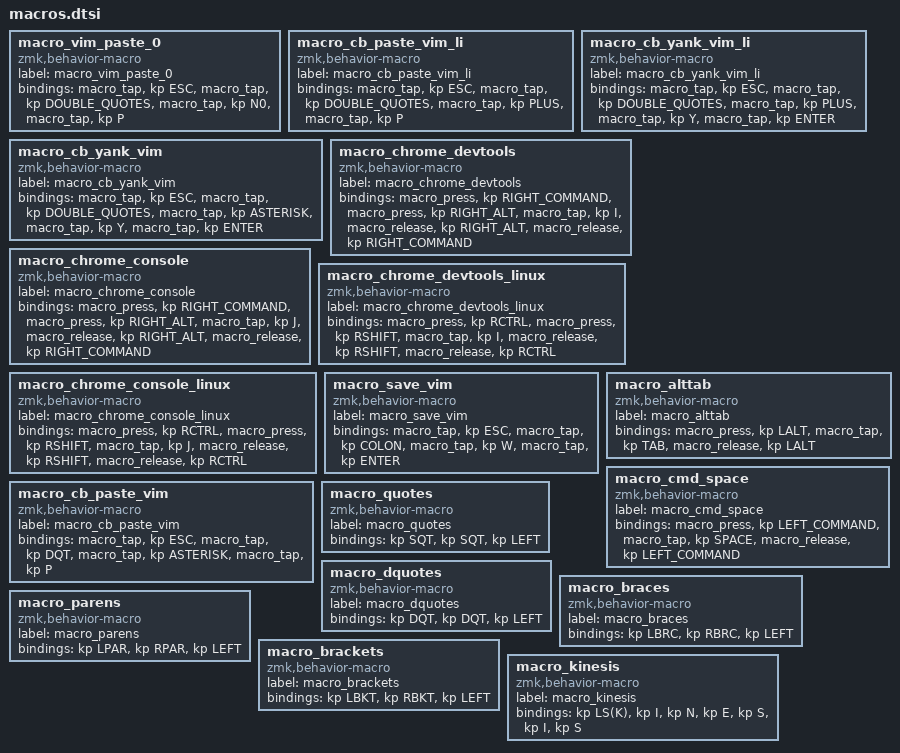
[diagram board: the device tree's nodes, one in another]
macro_vim_paste_0: macro_vim_paste_0{
compatible = "zmk,behavior-macro";
label = "macro_vim_paste_0";
#binding-cells = <0>;
bindings = <&macro_tap &kp ESC>, <&macro_tap &kp DOUBLE_QUOTES>, <&macro_tap &kp N0>, <&macro_tap &kp P>;
};
macro_cb_paste_vim_li: macro_cb_paste_vim_li{
compatible = "zmk,behavior-macro";
label = "macro_cb_paste_vim_li";
#binding-cells = <0>;
bindings = <&macro_tap &kp ESC>, <&macro_tap &kp DOUBLE_QUOTES>, <&macro_tap &kp PLUS>, <&macro_tap &kp P>;
};
macro_cb_yank_vim_li: macro_cb_yank_vim_li{
compatible = "zmk,behavior-macro";
label = "macro_cb_yank_vim_li";
#binding-cells = <0>;
bindings = <&macro_tap &kp ESC>, <&macro_tap &kp DOUBLE_QUOTES>, <&macro_tap &kp PLUS>, <&macro_tap &kp Y>, <&macro_tap &kp ENTER>;
};
macro_cb_yank_vim: macro_cb_yank_vim{
compatible = "zmk,behavior-macro";
label = "macro_cb_yank_vim";
#binding-cells = <0>;
bindings = <&macro_tap &kp ESC>, <&macro_tap &kp DOUBLE_QUOTES>, <&macro_tap &kp ASTERISK>, <&macro_tap &kp Y>, <&macro_tap &kp ENTER>;
};
macro_chrome_devtools: macro_chrome_devtools{
compatible = "zmk,behavior-macro";
label = "macro_chrome_devtools";
#binding-cells = <0>;
bindings = <&macro_press &kp RIGHT_COMMAND>, <&macro_press &kp RIGHT_ALT>, <&macro_tap &kp I>, <&macro_release &kp RIGHT_ALT>, <&macro_release &kp RIGHT_COMMAND>;
};
macro_chrome_console: macro_chrome_console{
compatible = "zmk,behavior-macro";
label = "macro_chrome_console";
#binding-cells = <0>;
bindings = <&macro_press &kp RIGHT_COMMAND>, <&macro_press &kp RIGHT_ALT>, <&macro_tap &kp J>, <&macro_release &kp RIGHT_ALT>, <&macro_release &kp RIGHT_COMMAND>;
};
macro_chrome_devtools_linux: macro_chrome_devtools_linux{
compatible = "zmk,behavior-macro";
label = "macro_chrome_devtools_linux";
#binding-cells = <0>;
bindings = <&macro_press &kp RCTRL>, <&macro_press &kp RSHIFT>, <&macro_tap &kp I>, <&macro_release &kp RSHIFT>, <&macro_release &kp RCTRL>;
};
macro_chrome_console_linux: macro_chrome_console_linux{
compatible = "zmk,behavior-macro";
label = "macro_chrome_console_linux";
#binding-cells = <0>;
bindings = <&macro_press &kp RCTRL>, <&macro_press &kp RSHIFT>, <&macro_tap &kp J>, <&macro_release &kp RSHIFT>, <&macro_release &kp RCTRL>;
};
macro_save_vim: macro_save_vim{
compatible = "zmk,behavior-macro";
label = "macro_save_vim";
#binding-cells = <0>;
bindings = <&macro_tap &kp ESC>, <&macro_tap &kp COLON>, <&macro_tap &kp W>, <&macro_tap &kp ENTER>;
};
macro_cb_paste_vim: macro_cb_paste_vim{
compatible = "zmk,behavior-macro";
label = "macro_cb_paste_vim";
#binding-cells = <0>;
bindings = <&macro_tap &kp ESC>, <&macro_tap &kp DQT>, <&macro_tap &kp ASTERISK>, <&macro_tap &kp P>;
};
macro_alttab: macro_alttab{
compatible = "zmk,behavior-macro";
label = "macro_alttab";
#binding-cells = <0>;
bindings = <&macro_press &kp LALT>, <&macro_tap &kp TAB>, <&macro_release &kp LALT>;
};
macro_cmd_space: macro_cmd_space{
compatible = "zmk,behavior-macro";
label = "macro_cmd_space";
#binding-cells = <0>;
bindings = <&macro_press &kp LEFT_COMMAND>, <&macro_tap &kp SPACE>, <&macro_release &kp LEFT_COMMAND>;
};
macro_quotes: macro_quotes{
compatible = "zmk,behavior-macro";
label = "macro_quotes";
#binding-cells = <0>;
bindings = <&kp SQT>, <&kp SQT>, <&kp LEFT>;
};
macro_dquotes: macro_dquotes{
compatible = "zmk,behavior-macro";
label = "macro_dquotes";
#binding-cells = <0>;
bindings = <&kp DQT>, <&kp DQT>, <&kp LEFT>;
};
macro_braces: macro_braces{
compatible = "zmk,behavior-macro";
label = "macro_braces";
#binding-cells = <0>;
bindings = <&kp LBRC>, <&kp RBRC>, <&kp LEFT>;
};
macro_parens: macro_parens{
compatible = "zmk,behavior-macro";
label = "macro_parens";
#binding-cells = <0>;
bindings = <&kp LPAR>, <&kp RPAR>, <&kp LEFT>;
};
macro_brackets: macro_brackets{
compatible = "zmk,behavior-macro";
label = "macro_brackets";
#binding-cells = <0>;
bindings = <&kp LBKT>, <&kp RBKT>, <&kp LEFT>;
};
macro_kinesis: macro_kinesis{
compatible = "zmk,behavior-macro";
label = "macro_kinesis";
#binding-cells = <0>;
bindings = <&kp LS(K)>, <&kp I>, <&kp N>, <&kp E>, <&kp S>, <&kp I>, <&kp S>;
};
